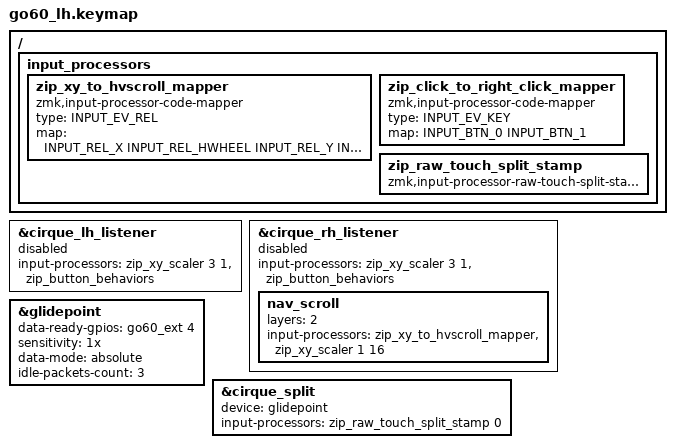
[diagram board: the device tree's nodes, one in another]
#define ZMK_POINTING_DEFAULT_MOVE_VAL 1200
#define ZMK_POINTING_DEFAULT_SCRL_VAL 25

#include <input/processors.dtsi>
#include <zephyr/dt-bindings/input/input-event-codes.h>
#include <zephyr/dt-bindings/gpio/gpio.h>
#include <dt-bindings/zmk/input_transform.h>

#include "positions_go60.dtsi"
#include "shared.dtsi"

/* ── Go60-specific: custom input processor + trackpad listeners ── */

/ {
    input_processors {
        /* Two-axis scroll mapper, kept name-for-name in sync with
         * go60_rh.keymap so the two files do not drift. Nothing on this
         * half actually uses it: the listeners below are disabled and the
         * central does all the input processing. */
        zip_xy_to_hvscroll_mapper: zip_xy_to_hvscroll_mapper {
            compatible = "zmk,input-processor-code-mapper";
            #input-processor-cells = <0>;
            type = <INPUT_EV_REL>;
            map = <INPUT_REL_X INPUT_REL_HWHEEL
                   INPUT_REL_Y INPUT_REL_WHEEL>;
        };

        zip_click_to_right_click_mapper: zip_click_to_right_click_mapper {
            compatible = "zmk,input-processor-code-mapper";
            #input-processor-cells = <0>;
            type = <INPUT_EV_KEY>;
            map = <INPUT_BTN_0 INPUT_BTN_1>;
        };
    };
};

&cirque_lh_listener {
    input-processors = <&zip_xy_scaler 3 1>, <&zip_button_behaviors>;
};

&cirque_rh_listener {
    input-processors = <&zip_xy_scaler 3 1>, <&zip_button_behaviors>;
    nav_scroll {
        layers = <2>;
        input-processors = <&zip_xy_to_hvscroll_mapper>, <&zip_xy_scaler 1 16>;
    };
};

/* Left pad, under Zephyr's in-tree Cirque driver: absolute mode,
 * lift-off packets, and its own sensitivity (see below). The absolute
 * frames are forwarded to the central over the split link, where the
 * raw_touch_lh node (go60_rh.keymap) streams them as pad-id 1 and derives
 * the relative deltas. Since 2026-09-15 this pad is a DEDICATED SCROLL
 * PAD: the central's &cirque_lh_listener carries the scroll marker in its
 * base chain, so those deltas become two-axis wheel events (Standard
 * mode) or nothing at all (RawTouch mode, where the host scrolls from the
 * frames) - never pointer motion.
 *
 * sensitivity stays at the stock maximum "1x" here, unlike the right
 * pad's "2x" — the asymmetry is deliberate; see the inline comment on the
 * property below.
 *
 * The pad's geometry/orientation live on the raw_touch_lh node on the
 * central, not here — and that node deliberately has NO tap-click: the
 * module suppresses taps for scroll-context touches, so tap-to-click is
 * inert on a dedicated scroll pad. */
&glidepoint {
    /* MoErgo's Go60 board DTS sets these four on &glidepoint under the
     * forked driver's names. Zephyr 3.5's edtlib errors on properties a
     * binding does not declare, so they must be deleted before the
     * in-tree names are set. */
    /delete-property/ dr-gpios;
    /delete-property/ rotate-90;
    /delete-property/ y-invert;
    /delete-property/ no-secondary-tap;

    data-ready-gpios = <&go60_ext 4 (GPIO_ACTIVE_HIGH | GPIO_PULL_DOWN)>;

    sensitivity = "1x";  /* NOT the right pad's 2x: sensitivity is hardware
                          * gain, and only the right pad has the baseline-
                          * drift jitter that 2x treats. This pad ran at 1x
                          * its whole life; halving its gain put marginal
                          * touches near the threshold (mid-touch dropouts,
                          * gestures ending early). Parity is behavioral,
                          * not register-identical. */

    /* Absolute reporting, for the raw touch stream. */
    data-mode = "absolute";


    /* MANDATORY. Written to the Pinnacle's Z_IDLE register; upstream
     * DEFAULTS IT TO 0, which emits no lift-off packets at all - the
     * module would never see a release, so no release frame, no momentum
     * and no tap-to-click. The forked driver hardcoded 3 in absolute
     * mode. */
    idle-packets-count = <3>;

    /* Deliberately NOT setting swap-xy / invert-y (the relative-mode
     * config did). Upstream applies invert-x/invert-y in BOTH modes, so
     * setting invert-y would bake the mirror into the streamed absolute
     * frames. Frames must stay raw: the orientation is declared on
     * raw_touch_lh instead, where the module applies it to the derived
     * pointer deltas and publishes it in the feature report for the
     * host. swap-xy is inert in absolute mode either way. */
};

/* ── Override: left half is now peripheral ── */
/* Forward local trackpad to central via split.
 *
 * The relay's processor chain runs on this half, before each event is
 * forwarded. The module's split-stamp processor sits there so every
 * absolute frame crosses the link with THIS half's sample time (one extra
 * vendor-typed input event, sent just ahead of the frame's sync). Without
 * it the central stamps the frame when it gets there, after the polled
 * wired hop, and the poll cadence shows up in the timestamps the host
 * derives velocity from (measured 2026-09-20 on captures/: RH pad
 * inter-frame spacing sd 0.3 ms, LH pad sd 1.4 ms with ~8% of pairs off
 * by a full 5 ms poll cycle - bimodal 0.3/22.8 ms at stock polling). The
 * central needs no change: raw_touch.c always understands the stamp.
 *
 * The cell is the relay's reg (cirque_split@0 -> 0), which the central
 * routes relayed events by. A cell, not a phandle back to the relay: that
 * would be a devicetree dependency cycle. */
/ {
    input_processors {
        zip_raw_touch_split_stamp: zip_raw_touch_split_stamp {
            compatible = "zmk,input-processor-raw-touch-split-stamp";
            #input-processor-cells = <1>;
        };
    };
};

&cirque_split {
    device = <&glidepoint>;
    input-processors = <&zip_raw_touch_split_stamp 0>;
};

/* Disable listeners (central handles all input processing) */
&cirque_lh_listener {
    status = "disabled";
};

&cirque_rh_listener {
    status = "disabled";
};
